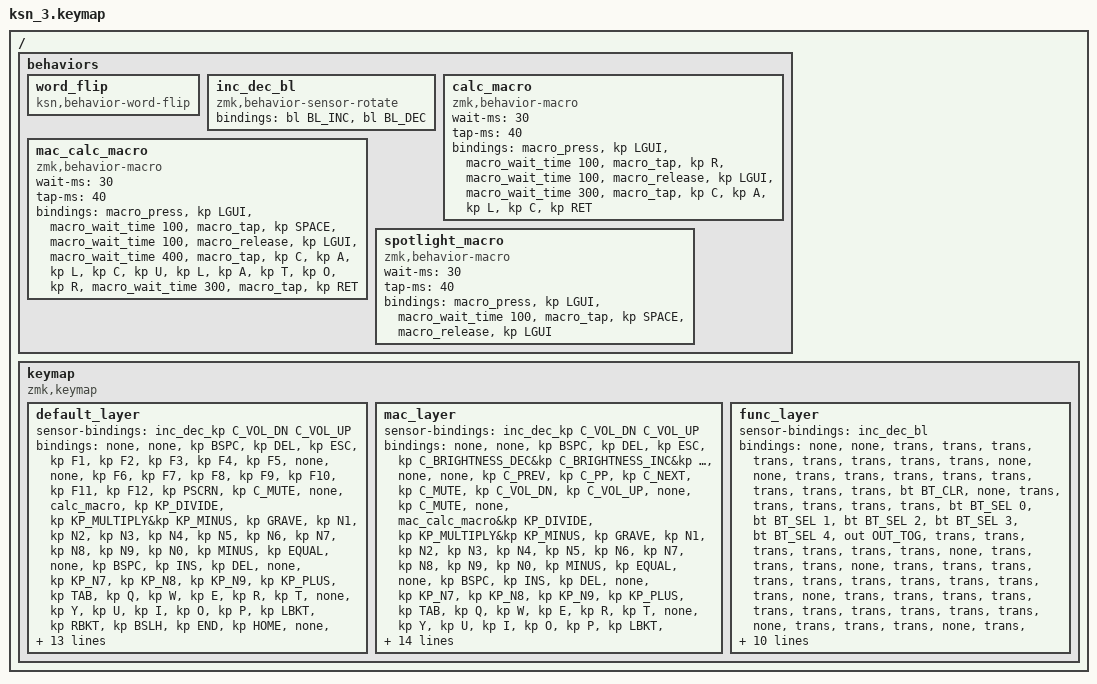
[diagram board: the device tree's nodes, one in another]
#include <behaviors.dtsi>
#include <dt-bindings/zmk/keys.h>
#include <dt-bindings/zmk/bt.h>
#include <dt-bindings/zmk/outputs.h>
#include <dt-bindings/zmk/backlight.h>

/* macOS F-row 전용 커스텀 consumer usage (ZMK 코어 keys.h에 없어 직접 정의):
   - C_MISSION_CONTROL: Consumer Page(0x0C) usage 0x29F. 공식 USB HID Usage
     Tables엔 없지만 QMK가 코어 키코드로 채택했고(KC_MISSION_CONTROL, PR #19884)
     macOS가 실제로 인식하는 값.
   - C_DICTATION: Consumer Page(0x0C) usage 0xD8. 공식 USB HID Usage Tables
     HUTRR99 "Start or Stop Voice Dictation Session" 표준 usage.
   F4(Spotlight)는 전용 HID usage가 불확실해 Cmd+Space 매크로(&spotlight_macro,
   아래 behaviors 참고)로 대체. F6(방해금지모드)은 실제 macOS가 보내는 코드가
   ZMK가 지원하지 않는 Generic Desktop 페이지(usage 0x9B)라 순정 방식 구현 불가 -
   확인 후 빈 키로 유지. */
#define C_MISSION_CONTROL ZMK_HID_USAGE(HID_USAGE_CONSUMER, 0x29F)
#define C_DICTATION       ZMK_HID_USAGE(HID_USAGE_CONSUMER, 0xD8)

/ {
    behaviors {
        /* 한/영 오타 자동 되돌리기 트리거. param: 0=Windows, 1=macOS.
           구현은 config/src/ksn3_word_flip.c (KSN-1에서 그대로 가져옴). */
        word_flip: word_flip {
            compatible = "ksn,behavior-word-flip";
            #binding-cells = <1>;
        };

        inc_dec_bl: inc_dec_bl {
            compatible = "zmk,behavior-sensor-rotate";
            #sensor-binding-cells = <0>;
            bindings = <&bl BL_INC>, <&bl BL_DEC>;
        };

        /* Windows 계산기 실행 매크로: KSN-1과 동일 (GUI+R -> "calc" -> Enter).
           왼쪽(peripheral) col1 row2 위치에 바인딩됨 (default_layer). */
        calc_macro: calc_macro {
            compatible = "zmk,behavior-macro";
            #binding-cells = <0>;
            wait-ms = <30>;
            tap-ms = <40>;
            bindings
                = <&macro_press &kp LGUI>
                , <&macro_wait_time 100>
                , <&macro_tap &kp R>
                , <&macro_wait_time 100>
                , <&macro_release &kp LGUI>
                , <&macro_wait_time 300>
                , <&macro_tap &kp C &kp A &kp L &kp C &kp RET>
                ;
        };

        /* macOS 계산기 실행 매크로: KSN-1과 동일 (Cmd+Space -> "calculator" -> Enter).
           같은 위치의 mac_layer 바인딩. */
        mac_calc_macro: mac_calc_macro {
            compatible = "zmk,behavior-macro";
            #binding-cells = <0>;
            wait-ms = <30>;
            tap-ms = <40>;
            bindings
                = <&macro_press &kp LGUI>
                , <&macro_wait_time 100>
                , <&macro_tap &kp SPACE>
                , <&macro_wait_time 100>
                , <&macro_release &kp LGUI>
                , <&macro_wait_time 400>
                , <&macro_tap &kp C &kp A &kp L &kp C &kp U &kp L &kp A &kp T &kp O &kp R>
                , <&macro_wait_time 300>
                , <&macro_tap &kp RET>
                ;
        };

        /* macOS Spotlight 검색 실행 매크로 (Cmd+Space). F4 자리 전용(mac_layer) -
           2020년 이후 최신 맥 F4가 여는 것과 동일한 화면(Spotlight)을 염. */
        spotlight_macro: spotlight_macro {
            compatible = "zmk,behavior-macro";
            #binding-cells = <0>;
            wait-ms = <30>;
            tap-ms = <40>;
            bindings
                = <&macro_press &kp LGUI>
                , <&macro_wait_time 100>
                , <&macro_tap &kp SPACE>
                , <&macro_release &kp LGUI>
                ;
        };
    };

    keymap {
        compatible = "zmk,keymap";

        default_layer {
            /* 오른쪽(central)에만 인코더 있음: 볼륨 업/다운 */
            sensor-bindings = <&inc_dec_kp C_VOL_DN C_VOL_UP>;
            bindings = <
                &none          &none          &kp BSPC       &kp DEL        &kp ESC        &kp F1         &kp F2         &kp F3         &kp F4         &kp F5         &none          &none          &kp F6         &kp F7         &kp F8         &kp F9         &kp F10        &kp F11        &kp F12        &kp PSCRN      &kp C_MUTE     &none
                &calc_macro    &kp KP_DIVIDE  &kp KP_MULTIPLY&kp KP_MINUS   &kp GRAVE      &kp N1         &kp N2         &kp N3         &kp N4         &kp N5         &kp N6         &kp N7         &kp N8         &kp N9         &kp N0         &kp MINUS      &kp EQUAL      &none          &kp BSPC       &kp INS        &kp DEL        &none          
                &kp KP_N7      &kp KP_N8      &kp KP_N9      &kp KP_PLUS    &kp TAB        &kp Q          &kp W          &kp E          &kp R          &kp T          &none          &kp Y          &kp U          &kp I          &kp O          &kp P          &kp LBKT       &kp RBKT       &kp BSLH       &kp END        &kp HOME       &none          
                &kp KP_N4      &kp KP_N5      &kp KP_N6      &none          &kp CLCK       &kp A          &kp S          &kp D          &kp F          &kp G          &none          &kp H          &kp J          &kp K          &kp L          &kp SEMI       &kp SQT        &none          &kp RET        &kp PG_UP      &kp PG_DN      &none          
                &kp KP_N1      &kp KP_N2      &kp KP_N3      &kp KP_ENTER   &kp LSHFT      &kp Z          &none          &kp X          &kp C          &kp V          &kp B          &kp B          &kp N          &kp M          &kp COMMA      &kp DOT        &kp FSLH       &none          &kp RSHFT      &kp UP         &none          &none
                &kp KP_N0      &none          &kp KP_DOT     &none          &kp LCTRL      &kp LGUI       &none          &kp LALT       &mo 2          &none          &kp SPACE      &kp SPACE      &none          &kp RALT       &word_flip 0   &mo 2          &kp K_APP      &kp LANG_HANJA &kp LEFT       &kp DOWN       &kp RIGHT      &none >;
        };

        mac_layer {
            sensor-bindings = <&inc_dec_kp C_VOL_DN C_VOL_UP>;
            bindings = <
                &none          &none          &kp BSPC       &kp DEL        &kp ESC        &kp C_BRIGHTNESS_DEC&kp C_BRIGHTNESS_INC&kp C_MISSION_CONTROL&spotlight_macro&kp C_DICTATION&none          &none          &none          &kp C_PREV     &kp C_PP       &kp C_NEXT     &kp C_MUTE     &kp C_VOL_DN   &kp C_VOL_UP   &none          &kp C_MUTE     &none
                &mac_calc_macro&kp KP_DIVIDE  &kp KP_MULTIPLY&kp KP_MINUS   &kp GRAVE      &kp N1         &kp N2         &kp N3         &kp N4         &kp N5         &kp N6         &kp N7         &kp N8         &kp N9         &kp N0         &kp MINUS      &kp EQUAL      &none          &kp BSPC       &kp INS        &kp DEL        &none          
                &kp KP_N7      &kp KP_N8      &kp KP_N9      &kp KP_PLUS    &kp TAB        &kp Q          &kp W          &kp E          &kp R          &kp T          &none          &kp Y          &kp U          &kp I          &kp O          &kp P          &kp LBKT       &kp RBKT       &kp BSLH       &kp END        &kp HOME       &none          
                &kp KP_N4      &kp KP_N5      &kp KP_N6      &none          &kp CLCK       &kp A          &kp S          &kp D          &kp F          &kp G          &none          &kp H          &kp J          &kp K          &kp L          &kp SEMI       &kp SQT        &none          &kp RET        &kp PG_UP      &kp PG_DN      &none          
                &kp KP_N1      &kp KP_N2      &kp KP_N3      &kp KP_ENTER   &kp LSHFT      &kp Z          &none          &kp X          &kp C          &kp V          &kp B          &kp B          &kp N          &kp M          &kp COMMA      &kp DOT        &kp FSLH       &none          &kp RSHFT      &kp UP         &none          &none
                &kp KP_N0      &none          &kp KP_DOT     &none          &kp LCTRL      &kp LALT       &none          &kp LGUI       &mo 2          &none          &kp SPACE      &kp SPACE      &none          &kp CLCK       &word_flip 1   &mo 2          &trans             &kp LANG_HANJA &kp LEFT       &kp DOWN       &kp RIGHT      &none >;
        };

        /* 레이어 순서: default(0) → mac(1) → func(2).
           func_layer를 맨 위에 두어 FN(&mo 2)을 누르면 Windows/Mac 모드와 관계없이 항상 이 레이어가
           우선한다(ZMK는 켜진 레이어 중 번호가 높은 것부터 확인). &trans 자리는 아래 레이어로 통과하므로
           FN 없이 누른 키는 그대로 mac_layer/default_layer 동작을 한다. Mac 모드 전환은 &tog 1. */
        func_layer {
            sensor-bindings = <&inc_dec_bl>;
            bindings = <
                &none          &none          &trans         &trans         &trans         &trans         &trans         &trans         &trans         &trans         &none          &none          &trans         &trans         &trans         &trans         &trans         &trans         &trans         &trans         &bt BT_CLR     &none         
                &trans         &trans         &trans         &trans         &trans         &bt BT_SEL 0   &bt BT_SEL 1   &bt BT_SEL 2   &bt BT_SEL 3   &bt BT_SEL 4   &out OUT_TOG   &trans         &trans         &trans         &trans         &trans         &trans         &none          &trans         &trans         &trans         &none
                &trans         &trans         &trans         &trans         &trans         &trans         &trans         &trans         &trans         &trans         &none          &trans         &trans         &trans         &trans         &trans         &trans         &trans         &trans         &trans         &trans         &none         
                &trans         &trans         &trans         &none          &trans         &trans         &trans         &trans         &trans         &trans         &none          &trans         &trans         &trans         &trans         &trans         &trans         &none          &trans         &trans         &trans         &none         
                &trans         &trans         &trans         &trans         &trans         &trans         &none          &trans         &trans         &trans         &trans         &trans         &trans         &trans         &trans         &trans         &trans         &none          &trans         &trans         &none          &none         
                &trans         &none          &trans         &none          &trans         &trans         &none          &trans         &trans         &none          &trans         &trans         &none          &trans         &trans         &trans         &tog 1         &trans         &trans         &trans         &trans         &none                     >;
        };
    };
};
